# CY8C4245AXI_483 register map
File version: 0.1
CY8C42
Registers are 32-bit, read-write, no defined reset value unless marked. A register's access mark holds for its fields unless they carry their own. Offsets are from the block's base; lines under a group give offsets from that group; [hi:lo] are bit positions; {n}, {i} and the like mark numbered series; 'fields as' and 'values as' point back to an identical list; <NAME> marks a mode.

## Memory map
0x40060000 UART_1 size 0xFCD — Serial Communication Block
0x40070000 SPI size 0xFCD — Serial Communication Block

## SPI — Serial Communication Block
Base 0x40070000
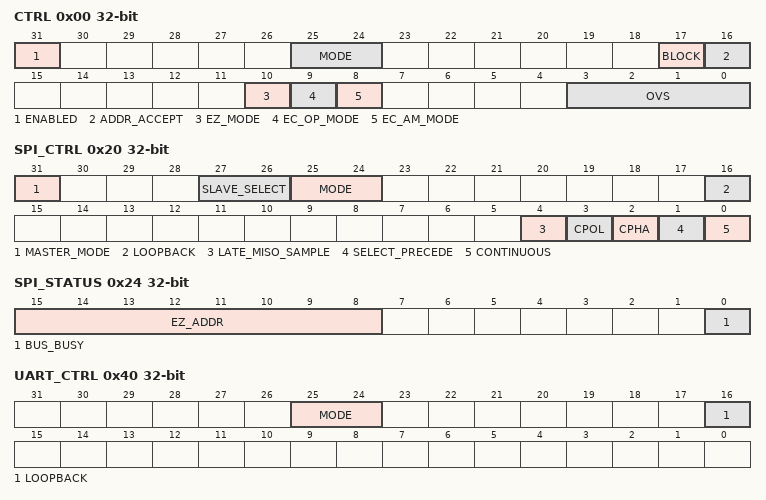
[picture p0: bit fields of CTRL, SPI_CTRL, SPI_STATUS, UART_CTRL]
0x00 CTRL — Generic control register: CTRL
  [31] ENABLED, [25:24] MODE, [17] BLOCK, [16] ADDR_ACCEPT, [10] EZ_MODE, [9] EC_OP_MODE, [8] EC_AM_MODE, [3:0] OVS
0x20 SPI_CTRL — SPI control register: SPI_CTRL
  [31] MASTER_MODE, [27:26] SLAVE_SELECT, [25:24] MODE, [16] LOOPBACK, [4] LATE_MISO_SAMPLE, [3] CPOL, [2] CPHA, [1] SELECT_PRECEDE, [0] CONTINUOUS
0x24 SPI_STATUS — SPI status register: SPI_STATUS
  [15:8] EZ_ADDR ro, [0] BUS_BUSY ro
0x40 UART_CTRL — Extended Configuration Register: CTRL
  [25:24] MODE, [16] LOOPBACK
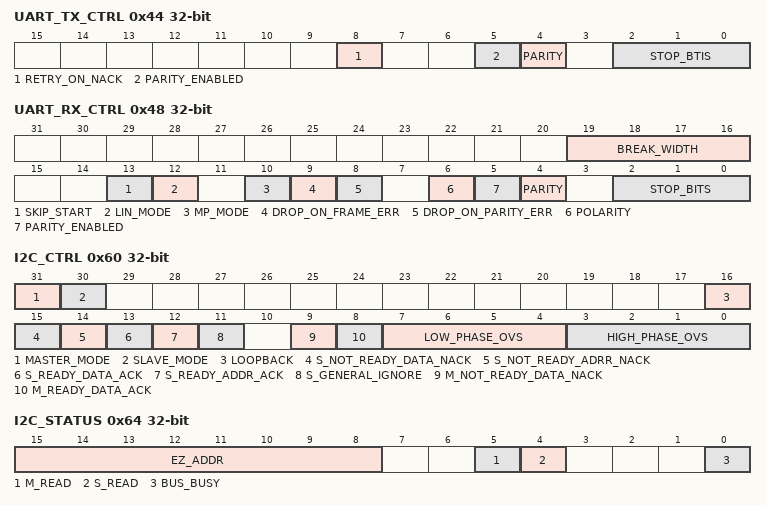
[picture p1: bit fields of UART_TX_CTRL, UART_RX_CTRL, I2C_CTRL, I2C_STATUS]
0x44 UART_TX_CTRL — Extended Configuration Register: UART_TX_CTRL
  [8] RETRY_ON_NACK, [5] PARITY_ENABLED, [4] PARITY, [2:0] STOP_BTIS
0x48 UART_RX_CTRL — Extended Configuration Register: UART_RX_CTRL
  [19:16] BREAK_WIDTH, [13] SKIP_START, [12] LIN_MODE, [10] MP_MODE, [9] DROP_ON_FRAME_ERR, [8] DROP_ON_PARITY_ERR, [6] POLARITY, [5] PARITY_ENABLED, [4] PARITY, [2:0] STOP_BITS
0x60 I2C_CTRL — Slave Adddress Register: I2C_CTRL
  [31] MASTER_MODE, [30] SLAVE_MODE, [16] LOOPBACK, [15] S_NOT_READY_DATA_NACK, [14] S_NOT_READY_ADRR_NACK, [13] S_READY_DATA_ACK, [12] S_READY_ADDR_ACK, [11] S_GENERAL_IGNORE, [9] M_NOT_READY_DATA_NACK, [8] M_READY_DATA_ACK, [7:4] LOW_PHASE_OVS, [3:0] HIGH_PHASE_OVS
0x64 I2C_STATUS — Slave Adddress Register: I2C_STATUS
  [15:8] EZ_ADDR, [5] M_READ, [4] S_READ, [0] BUS_BUSY
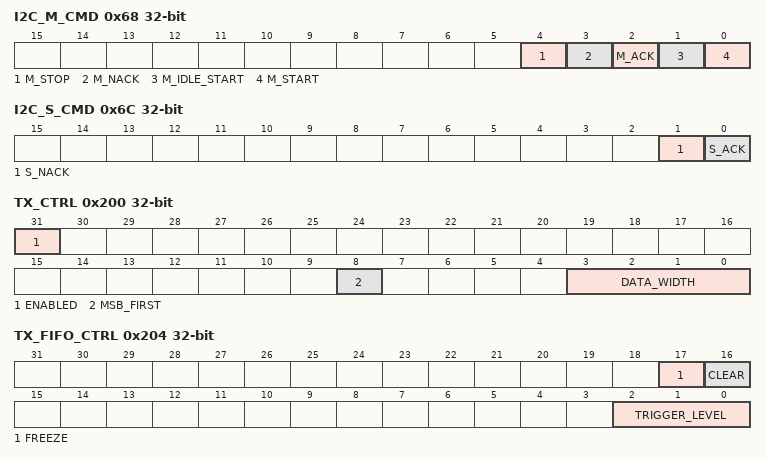
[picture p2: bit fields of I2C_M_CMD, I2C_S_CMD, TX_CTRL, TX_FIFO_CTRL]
0x68 I2C_M_CMD — Slave Adddress Register: I2C_M_CMD
  [4] M_STOP, [3] M_NACK, [2] M_ACK, [1] M_IDLE_START, [0] M_START
0x6C I2C_S_CMD — Slave Adddress Register: I2C_S_CMD
  [1] S_NACK, [0] S_ACK
0x200 TX_CTRL — Transmitter control register: TX_CTRL
  [31] ENABLED, [8] MSB_FIRST, [3:0] DATA_WIDTH
0x204 TX_FIFO_CTRL — Transmitter FIFO control register: TX_FIFO_CTRL
  [17] FREEZE, [16] CLEAR, [2:0] TRIGGER_LEVEL
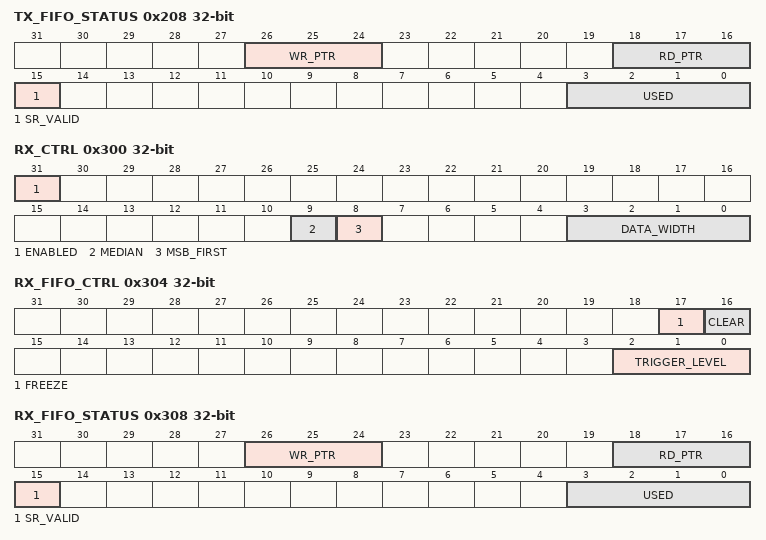
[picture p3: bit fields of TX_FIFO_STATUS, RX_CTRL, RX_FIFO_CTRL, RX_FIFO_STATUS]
0x208 TX_FIFO_STATUS — Transmitter FIFO status register: TX_FIFO_STATUS
  [26:24] WR_PTR, [18:16] RD_PTR, [15] SR_VALID, [3:0] USED
0x240 TX_FIFO_WR — Transmitter FIFO write register: TX_FIFO_WR
  [15:0] DATA
0x300 RX_CTRL — Receiver control register: RX_CTRL
  [31] ENABLED, [9] MEDIAN, [8] MSB_FIRST, [3:0] DATA_WIDTH
0x304 RX_FIFO_CTRL — Receiver FIFO control register: RX_FIFO_CTRL
  [17] FREEZE, [16] CLEAR, [2:0] TRIGGER_LEVEL
0x308 RX_FIFO_STATUS — Receiver FIFO status register: RX_FIFO_STATUS
  [26:24] WR_PTR, [18:16] RD_PTR, [15] SR_VALID, [3:0] USED
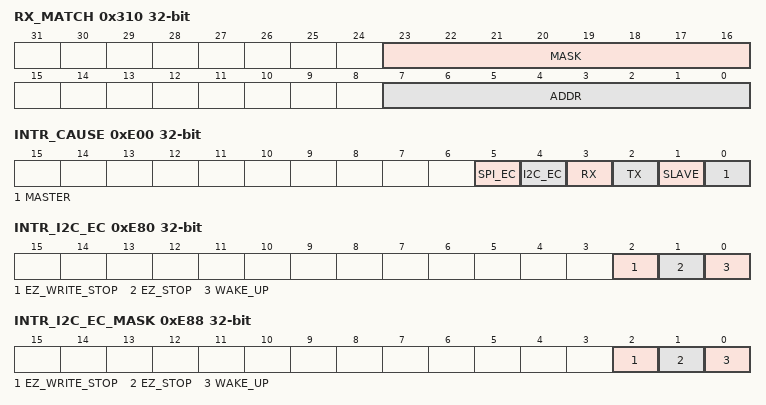
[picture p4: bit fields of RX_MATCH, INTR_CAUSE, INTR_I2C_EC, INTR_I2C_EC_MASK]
0x310 RX_MATCH — Slave Adddress Register: I2C_RX_MATCH
  [23:16] MASK, [7:0] ADDR
0x340 RX_FIFO_RD — Receiver FIFO read register: RX_FIFO_RD
  [15:0] DATA
0xE00 INTR_CAUSE — Active clocked interrupt signal register: INTR_CAUSE
  [5] SPI_EC, [4] I2C_EC, [3] RX, [2] TX, [1] SLAVE, [0] MASTER
0xE80 INTR_I2C_EC — Externally clocked I2C interrupt request register: INTR_SPI_EC
  [2] EZ_WRITE_STOP, [1] EZ_STOP, [0] WAKE_UP
0xE88 INTR_I2C_EC_MASK — Externally clocked I2C interrupt mask register: INTR_SPI_EC_MASK
  [2] EZ_WRITE_STOP, [1] EZ_STOP, [0] WAKE_UP
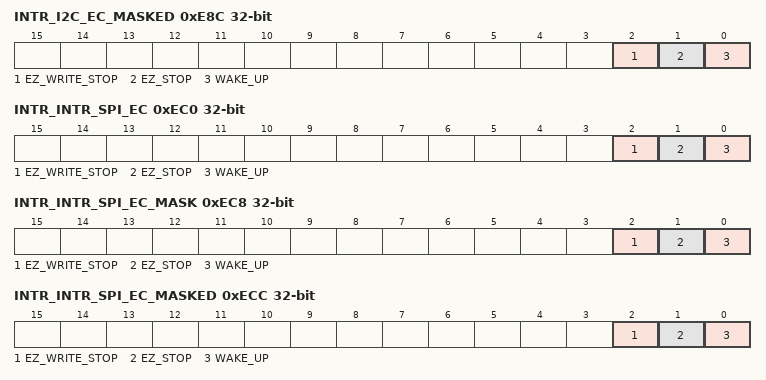
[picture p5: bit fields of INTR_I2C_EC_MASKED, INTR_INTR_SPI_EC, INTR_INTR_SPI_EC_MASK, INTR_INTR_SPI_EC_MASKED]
0xE8C INTR_I2C_EC_MASKED — Externally clocked SPI interrupt masked register: INTR_SPI_EC_MASKED
  [2] EZ_WRITE_STOP, [1] EZ_STOP, [0] WAKE_UP
0xEC0 INTR_INTR_SPI_EC — Externally clocked SPI interrupt request register: INTR_SPI_EC
  [2] EZ_WRITE_STOP, [1] EZ_STOP, [0] WAKE_UP
0xEC8 INTR_INTR_SPI_EC_MASK — Externally clocked SPI interrupt mask register: INTR_SPI_EC_MASK
  [2] EZ_WRITE_STOP, [1] EZ_STOP, [0] WAKE_UP
0xECC INTR_INTR_SPI_EC_MASKED — Externally clocked SPI interrupt masked register: INTR_SPI_EC_MASKED
  [2] EZ_WRITE_STOP, [1] EZ_STOP, [0] WAKE_UP
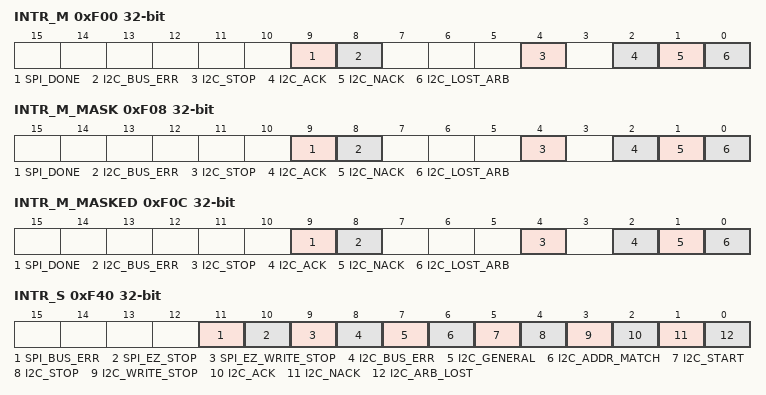
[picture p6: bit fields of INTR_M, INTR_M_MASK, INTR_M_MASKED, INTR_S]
0xF00 INTR_M — Slave Adddress Register: I2C_INTR_M
  [9] SPI_DONE, [8] I2C_BUS_ERR, [4] I2C_STOP, [2] I2C_ACK, [1] I2C_NACK, [0] I2C_LOST_ARB
0xF08 INTR_M_MASK — Slave Adddress Register: I2C_INTR_M_MASK
  fields as INTR_M
0xF0C INTR_M_MASKED — Slave Adddress Register: I2C_INTR_M_MASKED
  fields as INTR_M
0xF40 INTR_S — Slave interrupt request register: INTR_S
  [11] SPI_BUS_ERR, [10] SPI_EZ_STOP, [9] SPI_EZ_WRITE_STOP, [8] I2C_BUS_ERR, [7] I2C_GENERAL, [6] I2C_ADDR_MATCH, [5] I2C_START, [4] I2C_STOP, [3] I2C_WRITE_STOP, [2] I2C_ACK, [1] I2C_NACK, [0] I2C_ARB_LOST
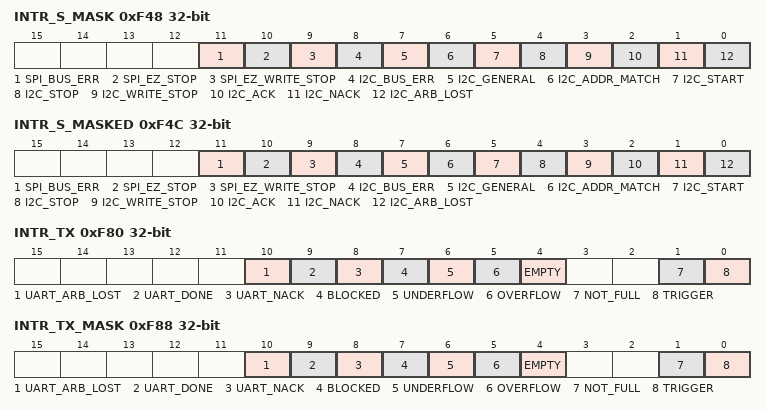
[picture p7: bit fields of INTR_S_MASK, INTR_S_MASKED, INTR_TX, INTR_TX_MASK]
0xF48 INTR_S_MASK — Slave interrupt mask register: INTR_S_MASK
  fields as INTR_S
0xF4C INTR_S_MASKED — Slave interrupt masked register: INTR_S_MASKED
  fields as INTR_S
0xF80 INTR_TX — Transmitter interrupt request register: INTR_TX
  [10] UART_ARB_LOST, [9] UART_DONE, [8] UART_NACK, [7] BLOCKED, [6] UNDERFLOW, [5] OVERFLOW, [4] EMPTY, [1] NOT_FULL, [0] TRIGGER
0xF88 INTR_TX_MASK — Transmitter interrupt mask request register: INTR_TX_MASK
  fields as INTR_TX
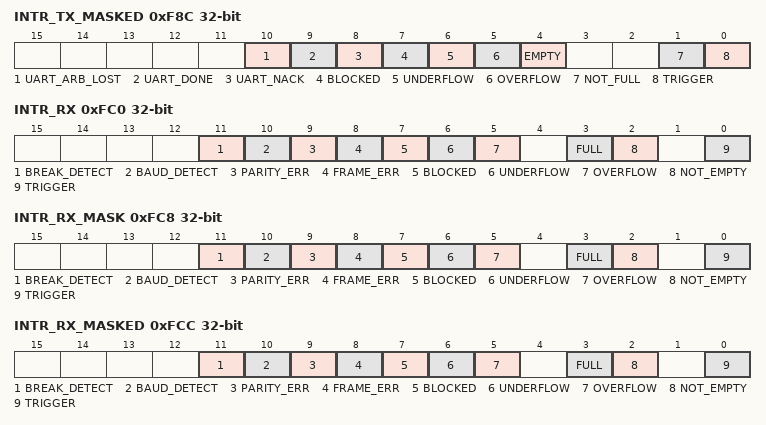
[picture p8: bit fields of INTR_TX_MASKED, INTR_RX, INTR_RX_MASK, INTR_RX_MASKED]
0xF8C INTR_TX_MASKED — Transmitter interrupt masked request register: INTR_TX_MASKED
  fields as INTR_TX
0xFC0 INTR_RX — Receiver interrupt request register: INTR_RX
  [11] BREAK_DETECT, [10] BAUD_DETECT, [9] PARITY_ERR, [8] FRAME_ERR, [7] BLOCKED, [6] UNDERFLOW, [5] OVERFLOW, [3] FULL, [2] NOT_EMPTY, [0] TRIGGER
0xFC8 INTR_RX_MASK — Receiver interrupt mask register: INTR_RX_MASK
  fields as INTR_RX
0xFCC INTR_RX_MASKED — Receiver interrupt masked register: INTR_RX_MASKED
  fields as INTR_RX

## UART_1 — Serial Communication Block
Base 0x40060000
Registers as SPI, without SPI_CTRL, SPI_STATUS, INTR_INTR_SPI_EC, INTR_INTR_SPI_EC_MASK, INTR_INTR_SPI_EC_MASKED; these are added or differ:
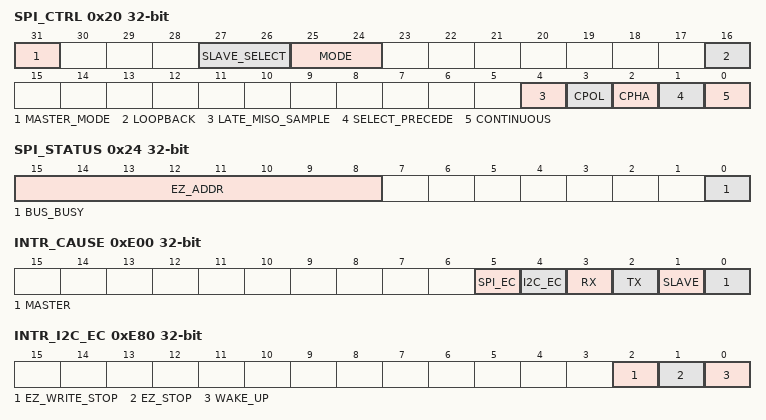
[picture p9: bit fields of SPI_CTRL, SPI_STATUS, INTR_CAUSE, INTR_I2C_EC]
0x20 SPI_CTRL — SPI control register: SPI_CTRL
  [31] MASTER_MODE, [27:26] SLAVE_SELECT, [25:24] MODE, [16] LOOPBACK, [4] LATE_MISO_SAMPLE, [3] CPOL, [2] CPHA, [1] SELECT_PRECEDE, [0] CONTINUOUS
0x24 SPI_STATUS — SPI status register: SPI_STATUS
  [15:8] EZ_ADDR ro, [0] BUS_BUSY ro
0xE00 INTR_CAUSE — Active clocked interrupt signal register: INTR_CAUSE
  [5] SPI_EC, [4] I2C_EC, [3] RX, [2] TX, [1] SLAVE, [0] MASTER
0xE80 INTR_I2C_EC — Externally clocked I2C interrupt request register: INTR_SPI_EC
  [2] EZ_WRITE_STOP, [1] EZ_STOP, [0] WAKE_UP
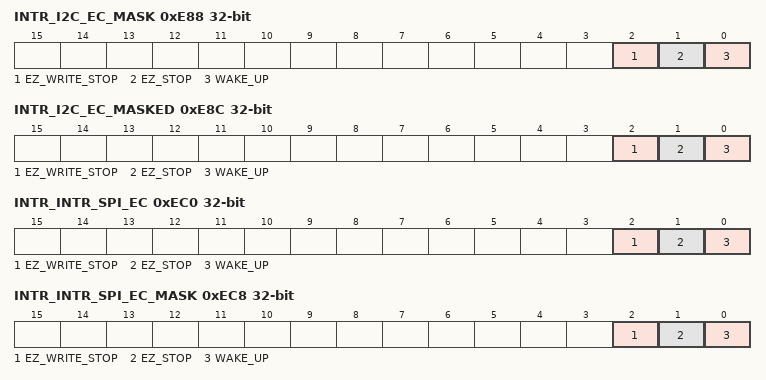
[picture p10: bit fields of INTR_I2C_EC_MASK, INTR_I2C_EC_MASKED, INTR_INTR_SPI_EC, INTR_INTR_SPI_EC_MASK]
0xE88 INTR_I2C_EC_MASK — Externally clocked I2C interrupt mask register: INTR_SPI_EC_MASK
  [2] EZ_WRITE_STOP, [1] EZ_STOP, [0] WAKE_UP
0xE8C INTR_I2C_EC_MASKED — Externally clocked SPI interrupt masked register: INTR_SPI_EC_MASKED
  [2] EZ_WRITE_STOP, [1] EZ_STOP, [0] WAKE_UP
0xEC0 INTR_INTR_SPI_EC — Externally clocked SPI interrupt request register: INTR_SPI_EC
  [2] EZ_WRITE_STOP, [1] EZ_STOP, [0] WAKE_UP
0xEC8 INTR_INTR_SPI_EC_MASK — Externally clocked SPI interrupt mask register: INTR_SPI_EC_MASK
  [2] EZ_WRITE_STOP, [1] EZ_STOP, [0] WAKE_UP
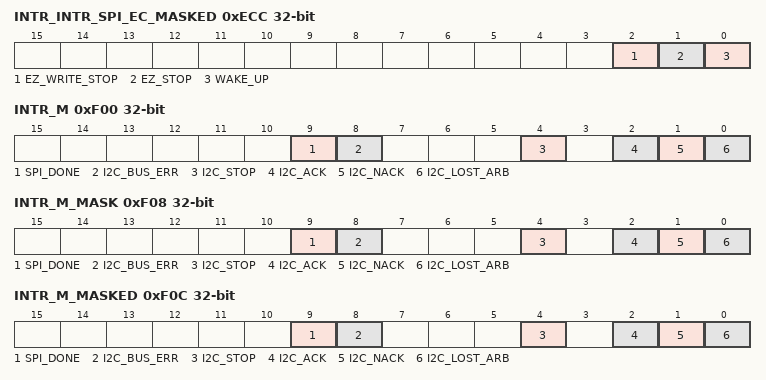
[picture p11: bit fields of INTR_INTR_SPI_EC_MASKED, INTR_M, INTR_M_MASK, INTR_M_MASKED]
0xECC INTR_INTR_SPI_EC_MASKED — Externally clocked SPI interrupt masked register: INTR_SPI_EC_MASKED
  [2] EZ_WRITE_STOP, [1] EZ_STOP, [0] WAKE_UP
0xF00 INTR_M — Slave Adddress Register: I2C_INTR_M
  [9] SPI_DONE, [8] I2C_BUS_ERR, [4] I2C_STOP, [2] I2C_ACK, [1] I2C_NACK, [0] I2C_LOST_ARB
0xF08 INTR_M_MASK — Slave Adddress Register: I2C_INTR_M_MASK
  fields as INTR_M
0xF0C INTR_M_MASKED — Slave Adddress Register: I2C_INTR_M_MASKED
  fields as INTR_M
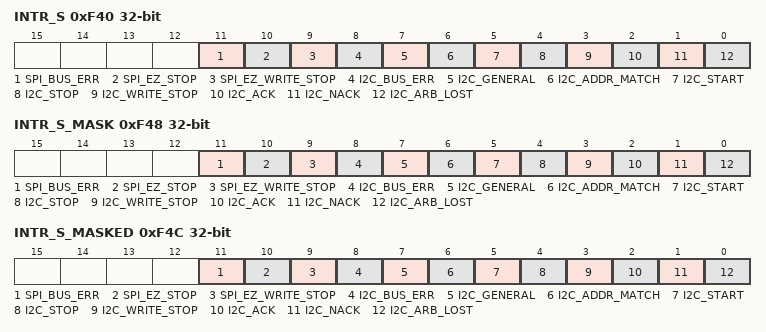
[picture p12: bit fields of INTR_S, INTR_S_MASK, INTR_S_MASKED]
0xF40 INTR_S — Slave interrupt request register: INTR_S
  fields as SPI.INTR_S
0xF48 INTR_S_MASK — Slave interrupt mask register: INTR_S_MASK
  fields as SPI.INTR_S
0xF4C INTR_S_MASKED — Slave interrupt masked register: INTR_S_MASKED
  fields as SPI.INTR_S
